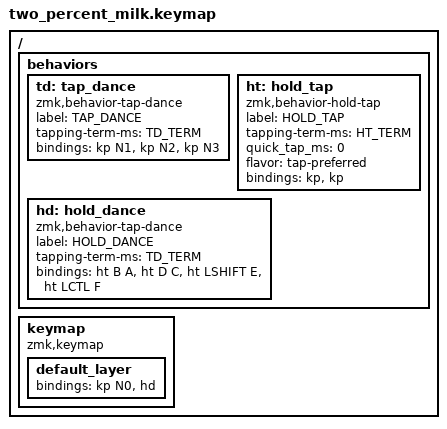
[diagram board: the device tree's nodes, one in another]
/*
 * Copyright (c) 2022 The ZMK Contributors
 *
 * SPDX-License-Identifier: MIT
 */

 #include <behaviors.dtsi>
 #include <dt-bindings/zmk/keys.h>
 #include <dt-bindings/zmk/bt.h>
 
 #define DEFAULT 0
 #define TD_TERM 200
 #define HT_TERM 200
 
 / {
    behaviors {
        td: tap_dance {
            compatible = "zmk,behavior-tap-dance";
            label = "TAP_DANCE";
            #binding-cells = <0>;
            tapping-term-ms = <TD_TERM>;
            bindings = <&kp N1>, <&kp N2>, <&kp N3>;
        };

        ht: hold_tap {
            compatible = "zmk,behavior-hold-tap";
            label = "HOLD_TAP";
            #binding-cells = <2>;
            tapping-term-ms = <HT_TERM>;
            quick_tap_ms = <0>;
            flavor = "tap-preferred";
            bindings = <&kp>, <&kp>;
        };

        hd: hold_dance {
            compatible = "zmk,behavior-tap-dance";
            label = "HOLD_DANCE";
            #binding-cells = <0>;
            tapping-term-ms = <TD_TERM>;
            bindings = <&ht B A>, <&ht D C>, <&ht LSHIFT E>, <&ht LCTL F>;
        };


    };

    keymap {
        compatible = "zmk,keymap";
 
        default_layer {
            bindings = <
                &kp N0 
                &hd
            >;
        };
    };
};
